# CY8C5868AXI_LP035 register map
File version: 0.1
CY8C58LP
Registers are 8-bit, read-write, no defined reset value unless marked. A register's access mark holds for its fields unless they carry their own. Offsets are from the block's base; lines under a group give offsets from that group; [hi:lo] are bit positions; {n}, {i} and the like mark numbered series; 'fields as' and 'values as' point back to an identical list; <NAME> marks a mode.

## Memory map
0x00000000 QuadDec_1
0x00000000 QuadDec_1_Cnt16
0x00000000 ADC_SAR_2 — SAR ADC
0x00000000 ADC_SAR_1 — SAR ADC
0x00000000 Counter_1

## QuadDec_1
Base 0x00000000
0x40006402 QuadDec_1_Cnt16_COUNTER 16-bit — Counter value
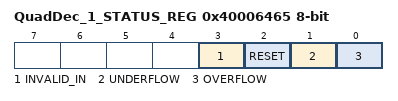
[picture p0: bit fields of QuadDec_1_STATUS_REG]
0x40006465 QuadDec_1_STATUS_REG — Quadrature Decoder Status Register
  [3] INVALID_IN ro — Invalid state transition on the A and B inputs
  [2] RESET ro — Counter Reset due index
  [1] UNDERFLOW ro — Counter underflow
  [0] OVERFLOW ro — Counter overflow

## QuadDec_1_Cnt16
Base 0x00000000
0x40006402 QuadDec_1_Cnt16_COUNTER 16-bit — UDB.A0 - Current Counter Value
0x40006422 QuadDec_1_Cnt16_PERIOD 16-bit — UDB.D0 - Assigned Period
0x40006432 QuadDec_1_Cnt16_COMPARE 16-bit — UDB.D1 - Assigned Compare Value
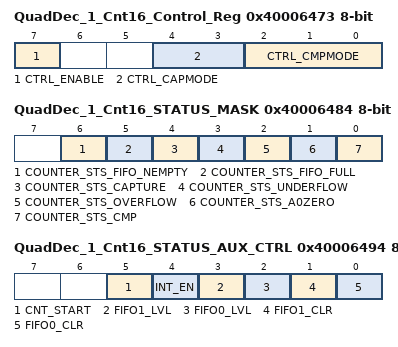
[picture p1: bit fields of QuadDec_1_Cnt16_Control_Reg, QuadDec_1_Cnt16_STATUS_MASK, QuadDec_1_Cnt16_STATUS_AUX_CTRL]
0x40006473 QuadDec_1_Cnt16_Control_Reg — UDB Control Register - Assigned Control Register Value
  [7] CTRL_ENABLE — Enable Counter
  [4:3] CTRL_CAPMODE — Capture mode
  [2:0] CTRL_CMPMODE — Compare mode
0x40006484 QuadDec_1_Cnt16_STATUS_MASK — UDB Status bits Interrupt Mask Enable Register
  [6] COUNTER_STS_FIFO_NEMPTY — FIFO Not Empty Status
  [5] COUNTER_STS_FIFO_FULL — FIFO Full Status
  [4] COUNTER_STS_CAPTURE — Capture Status
  [3] COUNTER_STS_UNDERFLOW — Underflow status
  [2] COUNTER_STS_OVERFLOW — Overflow status
  [1] COUNTER_STS_A0ZERO — A0 Zero ouput status
  [0] COUNTER_STS_CMP — Compare output status
0x40006494 QuadDec_1_Cnt16_STATUS_AUX_CTRL — UDB Auxilliary Control Register
  [5] CNT_START — FIFO0 clear
    0=E_CNT_START0 (Disable counter); 1=E_CNT_START1 (Enable counter)
  [4] INT_EN
    0=E_INT_EN0 (Interrupt disabled); 1=E_INT_EN1 (Interrupt enabled)
  [3] FIFO1_LVL — FIFO level
    0=E_FIFO_LVL_0 (FIFO LVL: input mode: FIFO not full; output mode: FIFO not empty); 1=E_FIFO_LVL_1 (FIFO LVL: input mode: FIFO at least 1/2 empty; output mode: FIFO at least 1/2 full)
  [2] FIFO0_LVL — FIFO level
    values as FIFO1_LVL
  [1] FIFO1_CLR — FIFO1 clear
    0=E_FIFO_CLR_0 (Normal FIFO operation); 1=E_FIFO_CLR_1 (Clear FIFO state)
  [0] FIFO0_CLR — FIFO0 clear
    values as FIFO1_CLR

## ADC_SAR_2 — SAR ADC
Base 0x00000000
0x40004616 SAR_TR0 — SAR trim register
{0x40005908+i} SAR_CSR{i} (i=0..6) — SAR status and control register {i}
0x40005B28 SAR_SW0 — SAR Analog Routing Register 0
{0x40005B28+i} SAR_SW{i} (i=2..4) — SAR Analog Routing Register {i}
0x40005B2E SAR_SW6 — SAR Analog Routing Register 6
0x40005B2F SAR_CLK — SAR Clock Selection Register
0x40005BA2 SAR_WRK 16-bit — SAR working register

## ADC_SAR_1 — SAR ADC
Base 0x00000000
0x40004614 SAR_TR0 — SAR trim register
{0x40005900+i} SAR_CSR{i} (i=0..6) — SAR status and control register {i}
0x40005B20 SAR_SW0 — SAR Analog Routing Register 0
{0x40005B20+i} SAR_SW{i} (i=2..4) — SAR Analog Routing Register {i}
0x40005B26 SAR_SW6 — SAR Analog Routing Register 6
0x40005B27 SAR_CLK — SAR Clock Selection Register
0x40005BA0 SAR_WRK 16-bit — SAR working register

## Counter_1
Base 0x00000000
0x40006505 Counter_1_COUNTER — UDB.A0 - Current Counter Value
0x40006525 Counter_1_PERIOD — UDB.D0 - Assigned Period
0x40006535 Counter_1_COMPARE — UDB.D1 - Assigned Compare Value
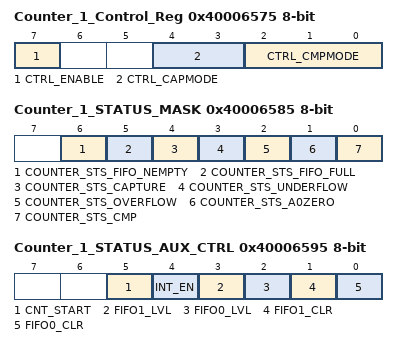
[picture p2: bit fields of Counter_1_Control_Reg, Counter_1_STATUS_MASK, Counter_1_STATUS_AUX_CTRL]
0x40006575 Counter_1_Control_Reg — UDB Control Register - Assigned Control Register Value
  [7] CTRL_ENABLE — Enable Counter
  [4:3] CTRL_CAPMODE — Capture mode
  [2:0] CTRL_CMPMODE — Compare mode
0x40006585 Counter_1_STATUS_MASK — UDB Status bits Interrupt Mask Enable Register
  fields as QuadDec_1_Cnt16.QuadDec_1_Cnt16_STATUS_MASK
0x40006595 Counter_1_STATUS_AUX_CTRL — UDB Auxilliary Control Register
  fields as QuadDec_1_Cnt16.QuadDec_1_Cnt16_STATUS_AUX_CTRL
